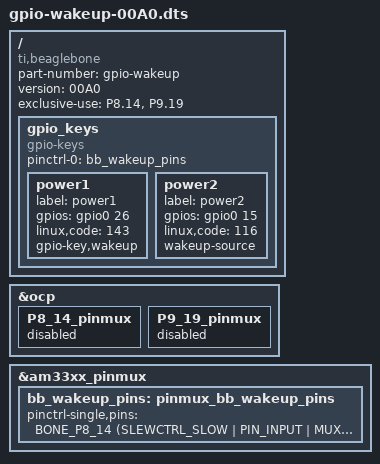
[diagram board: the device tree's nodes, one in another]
/*
 * Copyright (C) 2015 SoftPLC Corporation, Dick Hollenbeck <dick@softplc.com>
 *
 * This program is free software; you can redistribute it and/or modify
 * it under the terms of the GNU General Public License version 2 as
 * published by the Free Software Foundation.
 */
/dts-v1/;
/plugin/;

#include <dt-bindings/board/am335x-bbw-bbb-base.h>
#include <dt-bindings/pinctrl/am33xx.h>

/ {
	compatible = "ti,beaglebone", "ti,beaglebone-black", "ti,beaglebone-green";

	// identification
	part-number = "gpio-wakeup";
	version = "00A0";

	// the resources this cape uses.
	exclusive-use =
		"P8.14", // gpio0_26
		"P9.19"; // gpio0_15

	/*
	 * Free up the pins used by the cape from the pinmux helpers.
	 */
	fragment@0 {
		target = <&ocp>;
		__overlay__ {
			P8_14_pinmux { status = "disabled"; };	/* P8_14: gpio0_26 */
			P9_19_pinmux { status = "disabled"; };  /* P9_19: gpio0_15 */
		};
	};

	fragment@1 {
		target = <&am33xx_pinmux>;
		__overlay__ {
			bb_wakeup_pins: pinmux_bb_wakeup_pins {
				pinctrl-single,pins = <
					BONE_P8_14 (SLEWCTRL_SLOW | PIN_INPUT | MUX_MODE7)	/* P8_14: gpio0_26 */
					BONE_P9_19 (SLEWCTRL_SLOW | PIN_INPUT | MUX_MODE7)      /* P9_19: gpio0_15 */
				>;
			};
		};
	};

	fragment@2 {
		target-path="/";
		__overlay__ {
			gpio_keys {
				compatible = "gpio-keys";
				pinctrl-names = "default";
				pinctrl-0 = <&bb_wakeup_pins>;

				power1 {
					label = "power1";
					gpios = <&gpio0 26 0>;
					linux,code = <143>; /* System Wake Up */
					gpio-key,wakeup;
				};

				power2 {
					label = "power2";
					gpios = <&gpio0 15 0>;
					linux,code = <116>; /* System Power */
					wakeup-source;
				};
			};
                   };
        };

};

